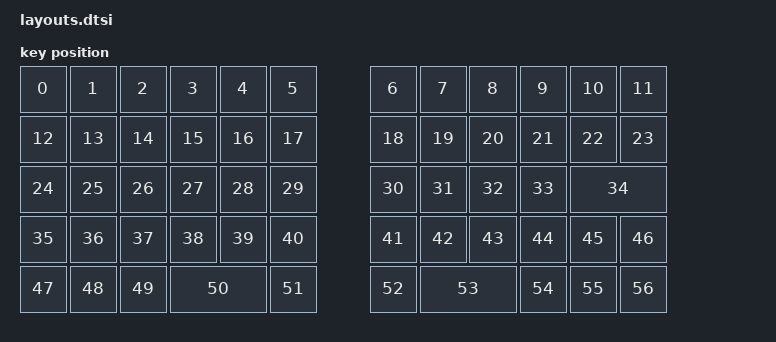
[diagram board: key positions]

#include <physical_layouts.dtsi>
/ {
    physical_layout0: physical_layout0 {
        compatible = "zmk,physical-layout";
        display-name = "Layout";
        keys
            = <&key_physical_attrs 100 100 (-50) 0 0 0 0>
			,<&key_physical_attrs 100 100 50 0 0 0 0>
			,<&key_physical_attrs 100 100 150 0 0 0 0>
			,<&key_physical_attrs 100 100 250 0 0 0 0>
			,<&key_physical_attrs 100 100 350 0 0 0 0>
			,<&key_physical_attrs 100 100 450 0 0 0 0>
			,<&key_physical_attrs 100 100 650 0 0 0 0>
			,<&key_physical_attrs 100 100 750 0 0 0 0>
			,<&key_physical_attrs 100 100 850 0 0 0 0>
			,<&key_physical_attrs 100 100 950 0 0 0 0>
			,<&key_physical_attrs 100 100 1050 0 0 0 0>
			,<&key_physical_attrs 100 100 1150 0 0 0 0>
			,<&key_physical_attrs 100 100 (-50) 100 0 0 0>
			,<&key_physical_attrs 100 100 50 100 0 0 0>
			,<&key_physical_attrs 100 100 150 100 0 0 0>
			,<&key_physical_attrs 100 100 250 100 0 0 0>
			,<&key_physical_attrs 100 100 350 100 0 0 0>
			,<&key_physical_attrs 100 100 450 100 0 0 0>
			,<&key_physical_attrs 100 100 650 100 0 0 0>
			,<&key_physical_attrs 100 100 750 100 0 0 0>
			,<&key_physical_attrs 100 100 850 100 0 0 0>
			,<&key_physical_attrs 100 100 950 100 0 0 0>
			,<&key_physical_attrs 100 100 1050 100 0 0 0>
			,<&key_physical_attrs 100 100 1150 100 0 0 0>
			,<&key_physical_attrs 100 100 (-50) 200 0 0 0>
			,<&key_physical_attrs 100 100 50 200 0 0 0>
			,<&key_physical_attrs 100 100 150 200 0 0 0>
			,<&key_physical_attrs 100 100 250 200 0 0 0>
			,<&key_physical_attrs 100 100 350 200 0 0 0>
			,<&key_physical_attrs 100 100 450 200 0 0 0>
			,<&key_physical_attrs 100 100 650 200 0 0 0>
			,<&key_physical_attrs 100 100 750 200 0 0 0>
			,<&key_physical_attrs 100 100 850 200 0 0 0>
			,<&key_physical_attrs 100 100 950 200 0 0 0>
			,<&key_physical_attrs 200 100 1050 200 0 0 0>
			,<&key_physical_attrs 100 100 (-50) 300 0 0 0>
			,<&key_physical_attrs 100 100 50 300 0 0 0>
			,<&key_physical_attrs 100 100 150 300 0 0 0>
			,<&key_physical_attrs 100 100 250 300 0 0 0>
			,<&key_physical_attrs 100 100 350 300 0 0 0>
			,<&key_physical_attrs 100 100 450 300 0 0 0>
			,<&key_physical_attrs 100 100 650 300 0 0 0>
			,<&key_physical_attrs 100 100 750 300 0 0 0>
			,<&key_physical_attrs 100 100 850 300 0 0 0>
			,<&key_physical_attrs 100 100 950 300 0 0 0>
			,<&key_physical_attrs 100 100 1050 300 0 0 0>
			,<&key_physical_attrs 100 100 1150 300 0 0 0>
			,<&key_physical_attrs 100 100 (-50) 400 0 0 0>
			,<&key_physical_attrs 100 100 50 400 0 0 0>
			,<&key_physical_attrs 100 100 150 400 0 0 0>
			,<&key_physical_attrs 200 100 250 400 0 0 0>
			,<&key_physical_attrs 100 100 450 400 0 0 0>
			,<&key_physical_attrs 100 100 650 400 0 0 0>
			,<&key_physical_attrs 200 100 750 400 0 0 0>
			,<&key_physical_attrs 100 100 950 400 0 0 0>
			,<&key_physical_attrs 100 100 1050 400 0 0 0>
			,<&key_physical_attrs 100 100 1150 400 0 0 0>
            ;
    };
};
    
